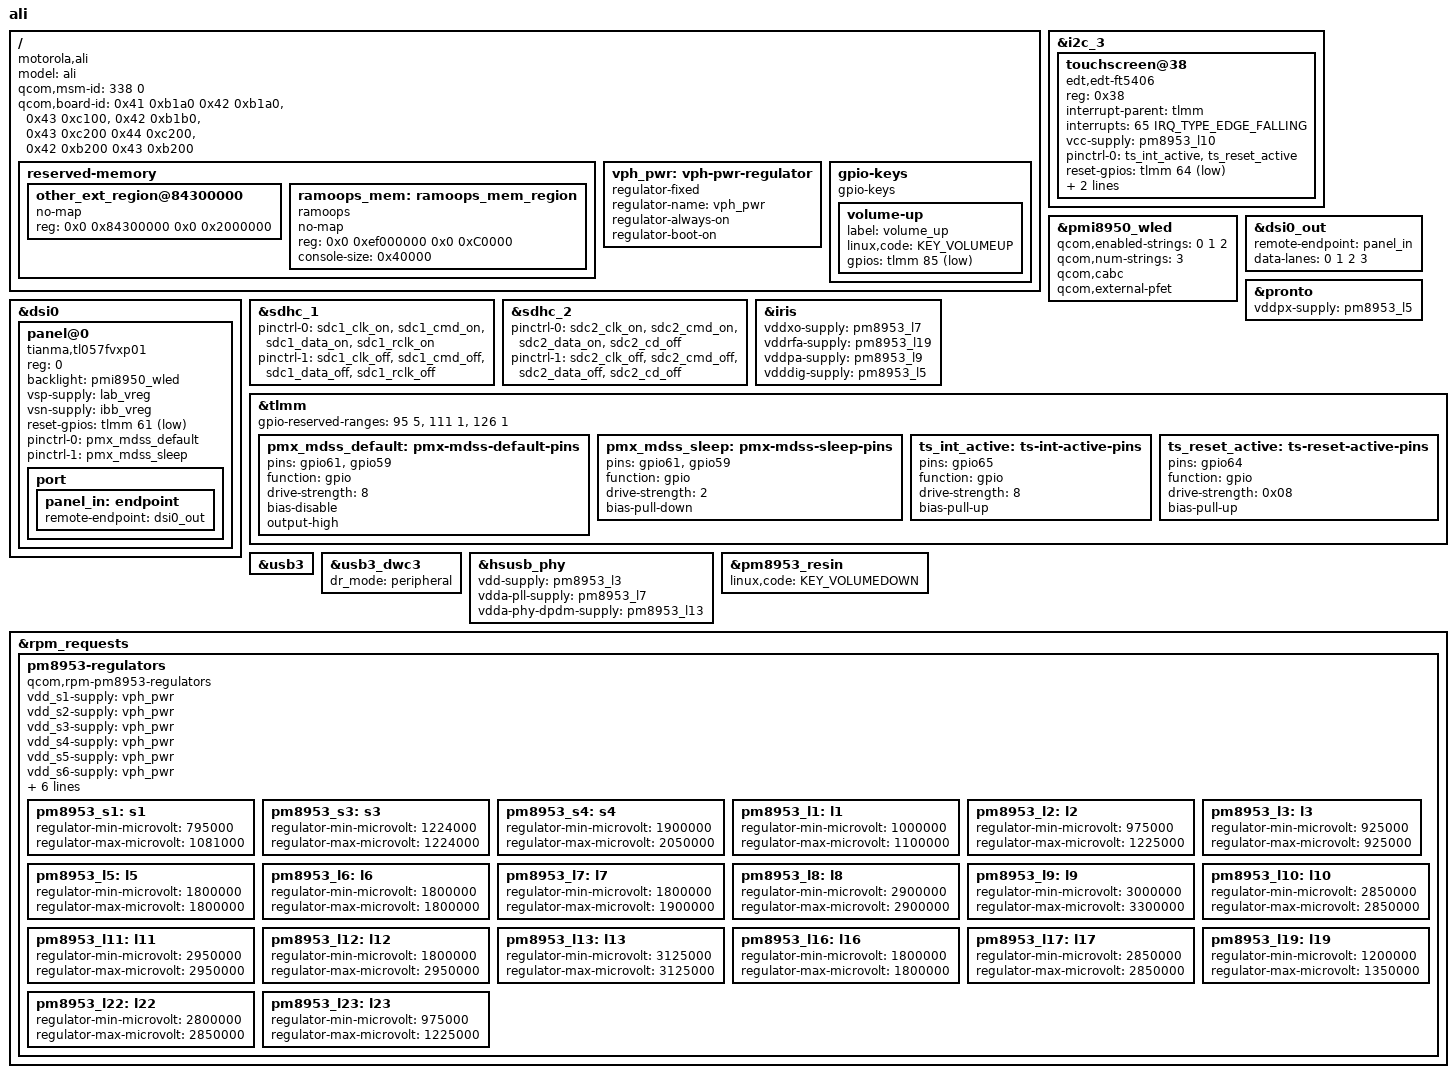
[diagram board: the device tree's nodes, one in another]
// SPDX-License-Identifier: GPL-2.0-only
// Copyright (c) 2020, The Linux Foundation. All rights reserved.

/dts-v1/;

#include "msm8953.dtsi"
#include "pm8953.dtsi"
#include "pmi8950.dtsi"

/ {
  model = "ali";
  compatible = "motorola,ali", "qcom,sdm450";
  qcom,msm-id = <338 0>;
  qcom,board-id = <0x41 0xb1a0 0x42 0xb1a0>, <0x43 0xc100>, <0x42 0xb1b0>, <0x43 0xc200 0x44 0xc200>, <0x42 0xb200 0x43 0xb200>;

  reserved-memory {
  	/delete-node/other_ext_region@85b00000;

  	other_ext_region@84300000 {
  		no-map;
  		reg = <0x0 0x84300000 0x0 0x2000000>;
  	};

  	ramoops_mem: ramoops_mem_region {
  		no-map;
  		compatible = "ramoops";
  		reg = <0x0 0xef000000 0x0 0xC0000>;
  		console-size = <0x40000>;
  	};

  };

  vph_pwr: vph-pwr-regulator {
  	compatible = "regulator-fixed";
  	regulator-name = "vph_pwr";
  	regulator-always-on;
  	regulator-boot-on;
  };

  gpio-keys {
  	compatible = "gpio-keys";

  	volume-up {
  		label = "volume_up";
  		linux,code = <KEY_VOLUMEUP>;
  		gpios = <&tlmm 85 GPIO_ACTIVE_LOW>;
  	};
  };
};

&i2c_3 {
	status = "okay";

	touchscreen@38 {
		compatible = "edt,edt-ft5406";
		reg = <0x38>;
		interrupt-parent = <&tlmm>;
		interrupts = <65 IRQ_TYPE_EDGE_FALLING>;
		vcc-supply = <&pm8953_l10>;

		pinctrl-names = "default";
		pinctrl-0 = <&ts_int_active &ts_reset_active>;

		reset-gpios = <&tlmm 64 GPIO_ACTIVE_LOW>;
		touchscreen-size-x = <1080>;
		touchscreen-size-y = <2160>;
	};
};

&pmi8950_wled {
	status = "okay";

	/* Don't copy-paste! See pmi8950.dtsi */

	qcom,enabled-strings = <0 1 2>;
	qcom,num-strings = <3>;

	qcom,cabc;
	qcom,external-pfet;
};

&dsi0 {
	panel@0 {
		compatible = "tianma,tl057fvxp01";
		reg = <0>;

		backlight = <&pmi8950_wled>;
		vsp-supply = <&lab_vreg>;
		vsn-supply = <&ibb_vreg>;
		reset-gpios = <&tlmm 61 GPIO_ACTIVE_LOW>;

		pinctrl-names = "default";
		pinctrl-0 = <&pmx_mdss_default>;
		pinctrl-1 = <&pmx_mdss_sleep>;

		port {
			panel_in: endpoint {
				remote-endpoint = <&dsi0_out>;
			};
		};
	};
};

&dsi0_out {
	remote-endpoint = <&panel_in>;
	data-lanes = <0 1 2 3>;
};

&sdhc_1 {
	status = "okay";

	pinctrl-names = "default", "sleep";
	pinctrl-0 = <&sdc1_clk_on &sdc1_cmd_on &sdc1_data_on  &sdc1_rclk_on>;
	pinctrl-1 = <&sdc1_clk_off &sdc1_cmd_off &sdc1_data_off &sdc1_rclk_off>;
};

&sdhc_2 {
	status = "okay";

	pinctrl-names = "default", "sleep";
	pinctrl-0 = <&sdc2_clk_on &sdc2_cmd_on &sdc2_data_on &sdc2_cd_off>;
	pinctrl-1 = <&sdc2_clk_off &sdc2_cmd_off &sdc2_data_off &sdc2_cd_off>;
};

&pronto {
	status = "okay";

	vddpx-supply = <&pm8953_l5>;
};

&iris {
	vddxo-supply = <&pm8953_l7>;
	vddrfa-supply = <&pm8953_l19>;
	vddpa-supply = <&pm8953_l9>;
	vdddig-supply = <&pm8953_l5>;
};

&tlmm {
	gpio-reserved-ranges = <95 5>, <111 1>, <126 1>;

	pmx_mdss_default: pmx-mdss-default-pins {
		pins = "gpio61", "gpio59";
		function = "gpio";
		drive-strength = <8>;
		bias-disable;
		output-high;
	};

	pmx_mdss_sleep: pmx-mdss-sleep-pins {
		pins = "gpio61", "gpio59";
		function = "gpio";
		drive-strength = <2>;
		bias-pull-down;
	};

	ts_int_active: ts-int-active-pins {
		pins = "gpio65";
		function = "gpio";
		drive-strength = <8>;
		bias-pull-up;
	};

	ts_reset_active: ts-reset-active-pins {
		pins = "gpio64";
		function = "gpio";
		drive-strength = <0x08>;
		bias-pull-up;
	};
};

&usb3 {
	status = "okay";
};

&usb3_dwc3 {
	dr_mode = "peripheral";
};

&hsusb_phy {
	status = "okay";

	vdd-supply = <&pm8953_l3>;
	vdda-pll-supply = <&pm8953_l7>;
	vdda-phy-dpdm-supply = <&pm8953_l13>;
};

&pm8953_resin {
	status = "okay";
	linux,code = <KEY_VOLUMEDOWN>;
};

&rpm_requests {
	pm8953-regulators {
		compatible = "qcom,rpm-pm8953-regulators";

		vdd_s1-supply = <&vph_pwr>;
		vdd_s2-supply = <&vph_pwr>;
		vdd_s3-supply = <&vph_pwr>;
		vdd_s4-supply = <&vph_pwr>;
		vdd_s5-supply = <&vph_pwr>;
		vdd_s6-supply = <&vph_pwr>;
		vdd_s7-supply = <&vph_pwr>;
		vdd_l1-supply = <&pm8953_s3>;
		vdd_l2_l3-supply = <&pm8953_s3>;
		vdd_l4_l5_l6_l7_l16_l19-supply = <&pm8953_s4>;
		vdd_l8_l11_l12_l13_l14_l15-supply = <&vph_pwr>;
		vdd_l9_l10_l17_l18_l22-supply = <&vph_pwr>;

		pm8953_s1: s1 {
			regulator-min-microvolt = <795000>;
			regulator-max-microvolt = <1081000>;
		};
		pm8953_s3: s3 {
			regulator-min-microvolt = <1224000>;
			regulator-max-microvolt = <1224000>;
		};
		pm8953_s4: s4 {
			regulator-min-microvolt = <1900000>;
			regulator-max-microvolt = <2050000>;
		};
		pm8953_l1: l1 {
			regulator-min-microvolt = <1000000>;
			regulator-max-microvolt = <1100000>;
		};
		pm8953_l2: l2 {
			regulator-min-microvolt = <975000>;
			regulator-max-microvolt = <1225000>;
		};
		pm8953_l3: l3 {
			regulator-min-microvolt = <925000>;
			regulator-max-microvolt = <925000>;
		};
		pm8953_l5: l5 {
			regulator-min-microvolt = <1800000>;
			regulator-max-microvolt = <1800000>;
		};
		pm8953_l6: l6 {
			regulator-min-microvolt = <1800000>;
			regulator-max-microvolt = <1800000>;
		};
		pm8953_l7: l7 {
			regulator-min-microvolt = <1800000>;
			regulator-max-microvolt = <1900000>;
		};
		pm8953_l8: l8 {
			regulator-min-microvolt = <2900000>;
			regulator-max-microvolt = <2900000>;
		};
		pm8953_l9: l9 {
			regulator-min-microvolt = <3000000>;
			regulator-max-microvolt = <3300000>;
		};
		pm8953_l10: l10 {
			regulator-min-microvolt = <2850000>;
			regulator-max-microvolt = <2850000>;
		};
		pm8953_l11: l11 {
			regulator-min-microvolt = <2950000>;
			regulator-max-microvolt = <2950000>;
		};
		pm8953_l12: l12 {
			regulator-min-microvolt = <1800000>;
			regulator-max-microvolt = <2950000>;
		};
		pm8953_l13: l13 {
			regulator-min-microvolt = <3125000>;
			regulator-max-microvolt = <3125000>;
		};
		pm8953_l16: l16 {
			regulator-min-microvolt = <1800000>;
			regulator-max-microvolt = <1800000>;
		};
		pm8953_l17: l17 {
			regulator-min-microvolt = <2850000>;
			regulator-max-microvolt = <2850000>;
		};
		pm8953_l19: l19 {
			regulator-min-microvolt = <1200000>;
			regulator-max-microvolt = <1350000>;
		};
		pm8953_l22: l22 {
			regulator-min-microvolt = <2800000>;
			regulator-max-microvolt = <2850000>;
		};
		pm8953_l23: l23 {
			regulator-min-microvolt = <975000>;
			regulator-max-microvolt = <1225000>;
		};
	};
};
